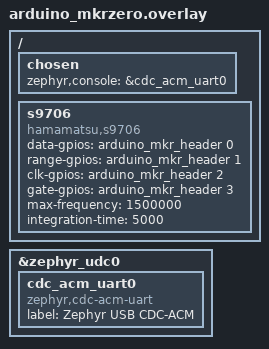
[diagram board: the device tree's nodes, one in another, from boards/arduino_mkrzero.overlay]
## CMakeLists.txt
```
# Copyright (c) 2026 Carl Zeiss AG
# SPDX-License-Identifier: Apache-2.0

cmake_minimum_required(VERSION 3.20.0)

find_package(Zephyr REQUIRED HINTS $ENV{ZEPHYR_BASE})
project(s9706)

file(GLOB app_sources src/*.c)
target_sources(app PRIVATE ${app_sources})
```

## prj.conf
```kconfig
# Copyright (c) 2026 Carl Zeiss AG
# SPDX-License-Identifier: Apache-2.0

CONFIG_SENSOR=y
CONFIG_LOG=y
CONFIG_SENSOR_LOG_LEVEL_DBG=y
```

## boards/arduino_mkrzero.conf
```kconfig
CONFIG_USB_DEVICE_STACK_NEXT=y

CONFIG_STDOUT_CONSOLE=y
CONFIG_SERIAL=y
CONFIG_USBD_CDC_ACM_CLASS=y
CONFIG_CDC_ACM_SERIAL_INITIALIZE_AT_BOOT=y

CONFIG_USBD_LOG_LEVEL_ERR=y
CONFIG_UDC_DRIVER_LOG_LEVEL_ERR=y
CONFIG_USBD_CDC_ACM_LOG_LEVEL_OFF=y
```

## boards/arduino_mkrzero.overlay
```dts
/*
 * Copyright (c) 2026 Carl Zeiss AG
 * SPDX-License-Identifier: Apache-2.0
 */

/ {
	chosen {
		zephyr,console = &cdc_acm_uart0;
	};

	s9706: s9706 {
		compatible = "hamamatsu,s9706";

		data-gpios = <&arduino_mkr_header 0 GPIO_PULL_UP>;
		range-gpios = <&arduino_mkr_header 1 (GPIO_ACTIVE_HIGH | GPIO_PUSH_PULL)>;
		clk-gpios = <&arduino_mkr_header 2 (GPIO_ACTIVE_HIGH | GPIO_PUSH_PULL)>;
		gate-gpios = <&arduino_mkr_header 3 (GPIO_ACTIVE_HIGH | GPIO_PUSH_PULL)>;

		max-frequency = <1500000>;
		integration-time = <5000>;
	};
};

&zephyr_udc0 {
	cdc_acm_uart0: cdc_acm_uart0 {
		compatible = "zephyr,cdc-acm-uart";
		label = "Zephyr USB CDC-ACM";
	};
};
```

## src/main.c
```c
/*
 * Copyright (c) 2026 Carl Zeiss AG
 * SPDX-License-Identifier: Apache-2.0
 */

#include <zephyr/kernel.h>
#include <zephyr/device.h>
#include <zephyr/drivers/sensor.h>
#include <stdio.h>

#include <zephyr/drivers/sensor/s9706.h>

#if !DT_HAS_COMPAT_STATUS_OKAY(hamamatsu_s9706)
#error "No hamamatsu,s9706 compatible node found in the device tree"
#endif

int main(void)
{
	const struct device *const s9706 = DEVICE_DT_GET_ANY(hamamatsu_s9706);
	struct sensor_value r, g, b;

	if (!device_is_ready(s9706)) {
		printf("Device %s is not ready.\n", s9706->name);
		return 0;
	}

	struct sensor_value integration_time;

	sensor_attr_get(s9706, SENSOR_CHAN_ALL, SENSOR_ATTR_S9706_INTEGRATION_TIME,
			&integration_time);

	printf("S9706 integration time : %d us\n", integration_time.val1);

	while (true) {
		if (sensor_sample_fetch(s9706)) {
			printf("Failed to fetch sample from S9706 device\n");
			return 0;
		}

		sensor_channel_get(s9706, SENSOR_CHAN_RED, &r);
		sensor_channel_get(s9706, SENSOR_CHAN_GREEN, &g);
		sensor_channel_get(s9706, SENSOR_CHAN_BLUE, &b);

		printf("S9706: R %d G %d B %d\n", r.val1, g.val1, b.val1);

		k_sleep(K_MSEC(500));
	}
}
```
